# STM32L4P5 register map
File version: 1.8
CPU: CM4 r0p1, little endian, MPU, FPU, 4 interrupt priority bits
Registers are 32-bit, read-write, reset 0x0 unless marked. A register's access mark holds for its fields unless they carry their own. Offsets are from the block's base; [hi:lo] are bit positions; 'fields as' and 'values as' point back to an identical list.

## DBGMCU — Debug support
Base 0xE0042000
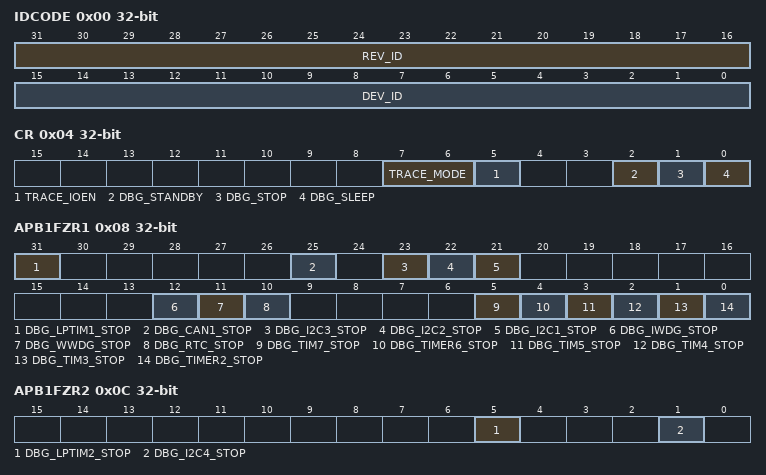
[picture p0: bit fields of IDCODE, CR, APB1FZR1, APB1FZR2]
0x00 IDCODE ro — MCU Device ID Code Register
  [31:16] REV_ID — Revision Identifier
  [15:0] DEV_ID — Device Identifier
0x04 CR — Debug MCU Configuration Register
  [7:6] TRACE_MODE — Trace pin assignment control
    0=Asynchronous (TRACE pin assignment for Asynchronous Mode); 1=Size1 (TRACE pin assignment for Synchronous Mode with a TRACEDATA size of 1); 2=Size2 (TRACE pin assignment for Synchronous Mode with a TRACEDATA size of 2); 3=Size4 (TRACE pin assignment for Synchronous Mode with a TRACEDATA size of 4)
  [5] TRACE_IOEN — Trace pin assignment control
    0=Disabled (Trace pins not assigned (default state)); 1=Enabled (Trace pins assigned)
  [2] DBG_STANDBY — Debug Standby Mode
    0=Disabled (Debug Standby Mode Disabled); 1=Enabled (Debug Standby Mode Enabled)
  [1] DBG_STOP — Debug Stop Mode
    0=Disabled (Debug Stop Mode Disabled); 1=Enabled (Debug Stop Mode Enabled)
  [0] DBG_SLEEP — Debug Sleep Mode
    0=Disabled (Debug Sleep Mode Disabled); 1=Enabled (Debug Sleep Mode Enabled)
0x08 APB1FZR1 — APB Low Freeze Register 1
  [31] DBG_LPTIM1_STOP — LPTIM1 counter stopped when core is halted
    0=Continue (LPTIMx counter clock is fed even if the core is halted); 1=Stop (LPTIMx counter clock is stopped when the core is halted)
  [25] DBG_CAN1_STOP — bxCAN stopped when core is halted
    0=NormalMode (Same behavior as in normal mode); 1=ReceiveRegistersFrozen (The bxCAN1 receive registers are frozen)
  [23] DBG_I2C3_STOP — I2C3 SMBUS timeout counter stopped when core is halted
    0=NormalMode (Same behavior as in normal mode); 1=SMBusTimeoutFrozen (I2Cx SMBUS timeout is frozen)
  [22] DBG_I2C2_STOP — I2C2 SMBUS timeout mode stopped when core is halted
    values as DBG_I2C3_STOP
  [21] DBG_I2C1_STOP — I2C1 SMBUS timeout mode stopped when core is halted
    values as DBG_I2C3_STOP
  [12] DBG_IWDG_STOP — Debug Independent Wachdog stopped when Core is halted
    0=Continue (The independent watchdog counter clock continues even if the core is halted); 1=Stop (The independent watchdog counter clock is stopped when the core is halted)
  [11] DBG_WWDG_STOP — Debug Window Wachdog stopped when Core is halted
    0=Continue (The window watchdog counter clock continues even if the core is halted); 1=Stop (The window watchdog counter clock is stopped when the core is halted)
  [10] DBG_RTC_STOP — Debug RTC stopped when Core is halted
    0=Continue (The clock of the RTC counter is fed even if the core is halted); 1=Stop (The clock of the RTC counter is stopped when the core is halted)
  [5] DBG_TIM7_STOP — TIM7 counter stopped when core is halted
    0=Continue (The counter clock of TIMx is fed even if the core is halted); 1=Stop (The counter clock of TIMx is stopped when the core is halted)
  [4] DBG_TIMER6_STOP — Debug Timer 6 stopped when Core is halted
    values as DBG_TIM7_STOP
  [3] DBG_TIM5_STOP — TIM5 counter stopped when core is halted
    values as DBG_TIM7_STOP
  [2] DBG_TIM4_STOP — TIM4 counter stopped when core is halted
    values as DBG_TIM7_STOP
  [1] DBG_TIM3_STOP — TIM3 counter stopped when core is halted
    values as DBG_TIM7_STOP
  [0] DBG_TIMER2_STOP — Debug Timer 2 stopped when Core is halted
    values as DBG_TIM7_STOP
0x0C APB1FZR2 — APB Low Freeze Register 2
  [5] DBG_LPTIM2_STOP — LPTIM2 counter stopped when core is halted
    values as APB1FZR1.DBG_LPTIM1_STOP
  [1] DBG_I2C4_STOP — I2C4 SMBUS timeout counter stopped when core is halted
    values as APB1FZR1.DBG_I2C3_STOP
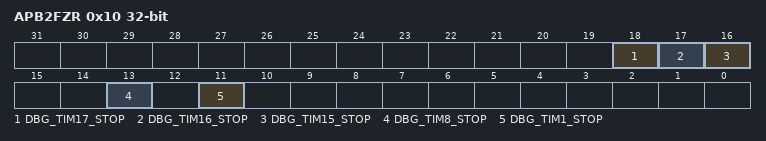
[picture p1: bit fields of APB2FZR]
0x10 APB2FZR — APB High Freeze Register
  [all] fields
    values as APB1FZR1.DBG_TIM7_STOP
  [18] DBG_TIM17_STOP — TIM17 counter stopped when core is halted
  [17] DBG_TIM16_STOP — TIM16 counter stopped when core is halted
  [16] DBG_TIM15_STOP — TIM15 counter stopped when core is halted
  [13] DBG_TIM8_STOP — TIM8 counter stopped when core is halted
  [11] DBG_TIM1_STOP — TIM1 counter stopped when core is halted
